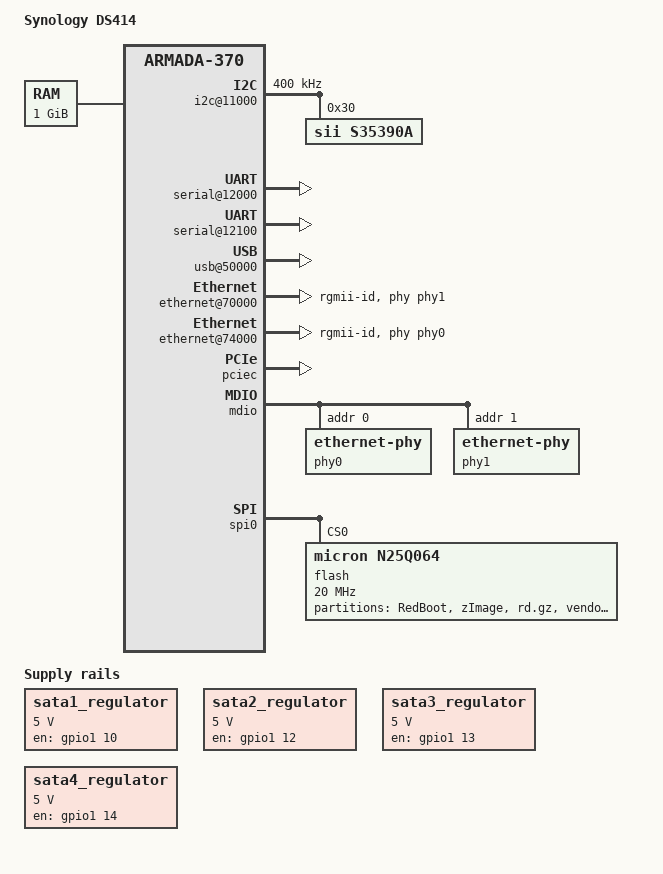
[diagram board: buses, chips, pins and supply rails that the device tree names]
/dts-v1/;
#include <dt-bindings/input/input.h>
#include <dt-bindings/gpio/gpio.h>
#include "armada-xp-mv78230.dtsi"
/ {
	model = "Synology DS414";
	compatible = "synology,ds414", "marvell,armadaxp-mv78230",
		     "marvell,armadaxp", "marvell,armada-370-xp";
	chosen {
		stdout-path = "serial0:115200n8";
	};
	memory@0 {
		device_type = "memory";
		reg = <0 0x00000000 0 0x40000000>;  
	};
	soc {
		ranges = <MBUS_ID(0xf0, 0x01) 0 0 0xf1000000 0x100000
			  MBUS_ID(0x01, 0x1d) 0 0 0xfff00000 0x100000
			  MBUS_ID(0x09, 0x09) 0 0 0xf1100000 0x10000
			  MBUS_ID(0x09, 0x05) 0 0 0xf1110000 0x10000>;
		internal-regs {
			rtc@10300 {
				status = "disabled";
			};
			i2c@11000 {
				clock-frequency = <400000>;
				status = "okay";
				s35390a: s35390a@30 {
					 compatible = "sii,s35390a";
					 reg = <0x30>;
				};
			};
			serial@12000 {
				status = "okay";
			};
			serial@12100 {
				status = "okay";
			};
			poweroff@12100 {
				compatible = "synology,power-off";
				reg = <0x12100 0x100>;
				clocks = <&coreclk 0>;
			};
			usb@50000 {
				status = "okay";
			};
			ethernet@70000 {
				status = "okay";
				pinctrl-0 = <&ge0_rgmii_pins>;
				pinctrl-names = "default";
				phy = <&phy1>;
				phy-mode = "rgmii-id";
			};
			ethernet@74000 {
				pinctrl-0 = <&ge1_rgmii_pins>;
				pinctrl-names = "default";
				status = "okay";
				phy = <&phy0>;
				phy-mode = "rgmii-id";
			};
		};
	};
	sata1_regulator: sata1-regulator-1 {
		compatible = "regulator-fixed";
		regulator-name = "SATA1 Power";
		regulator-min-microvolt = <5000000>;
		regulator-max-microvolt = <5000000>;
		startup-delay-us = <2000000>;
		enable-active-high;
		regulator-always-on;
		regulator-boot-on;
		gpio = <&gpio1 10 GPIO_ACTIVE_HIGH>;
		pinctrl-0 = <&sata1_pwr_pin>;
		pinctrl-names = "default";
	};
	sata2_regulator: sata2-regulator-2 {
		compatible = "regulator-fixed";
		regulator-name = "SATA2 Power";
		regulator-min-microvolt = <5000000>;
		regulator-max-microvolt = <5000000>;
		startup-delay-us = <4000000>;
		enable-active-high;
		regulator-always-on;
		regulator-boot-on;
		gpio = <&gpio1 12 GPIO_ACTIVE_HIGH>;
		pinctrl-0 = <&sata2_pwr_pin>;
		pinctrl-names = "default";
	};
	sata3_regulator: sata3-regulator-3 {
		compatible = "regulator-fixed";
		regulator-name = "SATA3 Power";
		regulator-min-microvolt = <5000000>;
		regulator-max-microvolt = <5000000>;
		startup-delay-us = <6000000>;
		enable-active-high;
		regulator-always-on;
		regulator-boot-on;
		gpio = <&gpio1 13 GPIO_ACTIVE_HIGH>;
		pinctrl-0 = <&sata3_pwr_pin>;
		pinctrl-names = "default";
	};
	sata4_regulator: sata4-regulator-4 {
		compatible = "regulator-fixed";
		regulator-name = "SATA4 Power";
		regulator-min-microvolt = <5000000>;
		regulator-max-microvolt = <5000000>;
		startup-delay-us = <8000000>;
		enable-active-high;
		regulator-always-on;
		regulator-boot-on;
		gpio = <&gpio1 14 GPIO_ACTIVE_HIGH>;
		pinctrl-0 = <&sata4_pwr_pin>;
		pinctrl-names = "default";
	};
};
&pciec {
	status = "okay";
	pcie@1,0 {
		status = "okay";
	};
	pcie@5,0 {
		status = "okay";
	};
};
&mdio {
	phy0: ethernet-phy@0 {  
		reg = <0>;
	};
	phy1: ethernet-phy@1 {  
		reg = <1>;
	};
};
&pinctrl {
	sata1_pwr_pin: sata1-pwr-pin {
		marvell,pins = "mpp42";
		marvell,function = "gpio";
	};
	sata2_pwr_pin: sata2-pwr-pin {
		marvell,pins = "mpp44";
		marvell,function = "gpio";
	};
	sata3_pwr_pin: sata3-pwr-pin {
		marvell,pins = "mpp45";
		marvell,function = "gpio";
	};
	sata4_pwr_pin: sata4-pwr-pin {
		marvell,pins = "mpp46";
		marvell,function = "gpio";
	};
	sata1_pres_pin: sata1-pres-pin {
		marvell,pins = "mpp34";
		marvell,function = "gpio";
	};
	sata2_pres_pin: sata2-pres-pin {
		marvell,pins = "mpp35";
		marvell,function = "gpio";
	};
	sata3_pres_pin: sata3-pres-pin {
		marvell,pins = "mpp40";
		marvell,function = "gpio";
	};
	sata4_pres_pin: sata4-pres-pin {
		marvell,pins = "mpp41";
		marvell,function = "gpio";
	};
	syno_id_bit0_pin: syno-id-bit0-pin {
		marvell,pins = "mpp26";
		marvell,function = "gpio";
	};
	syno_id_bit1_pin: syno-id-bit1-pin {
		marvell,pins = "mpp28";
		marvell,function = "gpio";
	};
	syno_id_bit2_pin: syno-id-bit2-pin {
		marvell,pins = "mpp29";
		marvell,function = "gpio";
	};
	fan1_alarm_pin: fan1-alarm-pin {
		marvell,pins = "mpp33";
		marvell,function = "gpio";
	};
	fan2_alarm_pin: fan2-alarm-pin {
		marvell,pins = "mpp32";
		marvell,function = "gpio";
	};
};
&spi0 {
	status = "okay";
	flash@0 {
		#address-cells = <1>;
		#size-cells = <1>;
		compatible = "micron,n25q064", "jedec,spi-nor";
		reg = <0>;  
		spi-max-frequency = <20000000>;
		partition@0 {  
			label = "RedBoot";
			reg = <0x00000000 0x000d0000>;  
		};
		partition@c0000 {  
			label = "zImage";
			reg = <0x000d0000 0x002d0000>;  
		};
		partition@3a0000 {  
			label = "rd.gz";
			reg = <0x003a0000 0x00430000>;  
		};
		partition@7d0000 {  
			label = "vendor";
			reg = <0x007d0000 0x00010000>;  
		};
		partition@7e0000 {
			label = "RedBoot config";
			reg = <0x007e0000 0x00010000>;  
		};
		partition@7f0000 {
			label = "FIS directory";
			reg = <0x007f0000 0x00010000>;  
		};
	};
};
